# R7FA2A2AD register map
Vendor: Renesas Electronics Corporation; Series: RA2A2; File version: 1.20.02
CPU: CM23 r1p0, little endian, MPU, no FPU, VTOR, 2 interrupt priority bits, 32 interrupts
Registers are 8-bit, read-write, reset 0x0 unless marked. A register's access mark holds for its fields unless they carry their own. Offsets are from the block's base; [hi:lo] are bit positions; {n}, {i} and the like mark numbered series.

## AGTW0 — Low Power Asynchronous General Purpose Timer 0
Base 0x40084000
Same registers: AGTW1 0x40084100
0x00 AGT 32-bit reset 0xFFFFFFFF — AGT Counter Register
0x04 AGTCMA 32-bit reset 0xFFFFFFFF — AGT Compare Match A Register
0x08 AGTCMB 32-bit reset 0xFFFFFFFF — AGT Compare Match B Register
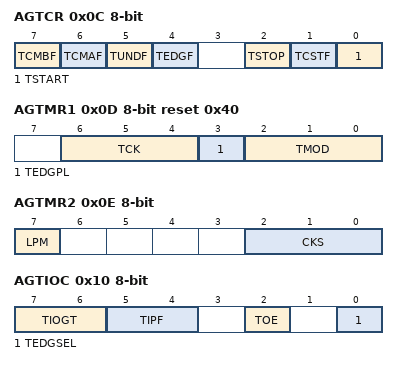
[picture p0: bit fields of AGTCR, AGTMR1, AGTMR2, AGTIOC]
0x0C AGTCR — AGT Control Register
  [7] TCMBF — Compare Match B Flag
    0=No match; 1=Match
  [6] TCMAF — Compare Match A Flag
    0=No match; 1=Match
  [5] TUNDF — Underflow Flag
    0=No underflow; 1=Underflow
  [4] TEDGF — Active Edge Judgment Flag
    0=No active edge received; 1=Active edge received
  [2] TSTOP wo — AGT Count Forced Stop
    0=Writing is invalid; 1=Count is forcibly stopped
  [1] TCSTF ro — AGT Count Status Flag
    0=Count stopped; 1=Count in progress
  [0] TSTART — AGT Count Start
    0=Count stops; 1=Count starts
0x0D AGTMR1 reset 0x40 — AGT Mode Register 1
  [6:4] TCK — Count Source
    0=PCLKB; 1=PCLKB/8; 3=PCLKB/2; 4=Divided clock AGTLCLK specified by CKS[2:0] bits in the AGTMR2 register; 5=Underflow event signal from AGTW0; 6=Divided clock AGTSCLK specified by CKS[2:0] bits in the AGTMR2 register; other=Others (Setting prohibited)
  [3] TEDGPL — Edge Polarity
    0=Single-edge; 1=Both-edge
  [2:0] TMOD — Operating Mode
    0=Timer mode; 1=Pulse output mode; 2=Event counter mode; 3=Pulse width measurement mode; 5=Pulse period measurement mode; other=Others (Setting prohibited)
0x0E AGTMR2 — AGT Mode Register 2
  [7] LPM — Low Power Mode
    0=Normal mode; 1=Low power mode
  [2:0] CKS — AGTLCLK or AGTSCLK Count Source Clock Frequency Division Ratio
    0=1/1; 1=1/2; 2=1/4; 3=1/8; 4=1/16; 5=1/32; 6=1/64; 7=1/128
0x0F AGTIOSEL — AGT Pin Select Register
  [4] TIES — AGTWIOn Pin Input Enable
    0=External event input is disabled during Software Standby mode; 1=External event input is enabled during Software Standby mode
0x10 AGTIOC — AGT I/O Control Register
  [7:6] TIOGT — Count Control
    0=Event is always counted; 1=Event is counted during polarity period specified for AGTWEEn pin; other=Others (Setting prohibited)
  [5:4] TIPF — Input Filter
    0=No filter; 1=Filter sampled at PCLKB; 2=Filter sampled at PCLKB/8; 3=Filter sampled at PCLKB/32
  [2] TOE — AGTWOn pin Output Enable
    0=AGTWOn pin output disabled; 1=AGTWOn pin output enabled
  [0] TEDGSEL — I/O Polarity Switch
0x11 AGTISR — AGT Event Pin Select Register
  [2] EEPS — AGTWEEn Polarity Selection
    0=An event is counted during the low-level period; 1=An event is counted during the high-level period
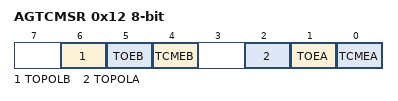
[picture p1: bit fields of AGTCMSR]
0x12 AGTCMSR — AGT Compare Match Function Select Register
  [6] TOPOLB — AGTWOBn Pin Polarity Select
    0=AGTWOBn pin output is started on low (normal output); 1=AGTWOBn pin output is started on high (inverted output)
  [5] TOEB — AGTWOBn Pin Output Enable
    0=AGTWOBn pin output disabled; 1=AGTWOBn pin output enabled
  [4] TCMEB — AGT Compare Match B Register Enable
    0=Compare match B register disabled; 1=Compare match B register enabled
  [2] TOPOLA — AGTWOAn Pin Polarity Select
    0=AGTWOAn pin output is started on low (normal output); 1=AGTWOAn pin output is started on high (inverted output)
  [1] TOEA — AGTWOAn Pin Output Enable
    0=AGTWOAn pin output disabled; 1=AGTWOAn pin output enabled
  [0] TCMEA — AGT Compare Match A Register Enable
    0=AGT Compare match A register disabled; 1=AGT Compare match A register enabled

## AGT0 — Low Power Asynchronous General Purpose Timer 0
Base 0x40084200
Same registers: AGT1 0x40084300, AGT2 0x40084400, AGT3 0x40084500, AGT4 0x40084600, AGT5 0x40084700, AGT6 0x40084800, AGT7 0x40084900
0x00 AGT 16-bit reset 0xFFFF — AGT Counter Register
0x02 AGTCMA 16-bit reset 0xFFFF — AGT Compare Match A Register
0x04 AGTCMB 16-bit reset 0xFFFF — AGT Compare Match B Register
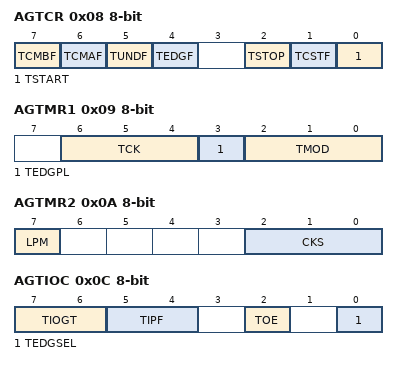
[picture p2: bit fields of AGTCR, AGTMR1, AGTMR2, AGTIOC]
0x08 AGTCR — AGT Control Register
  [7] TCMBF — Compare Match B Flag
    0=No match; 1=Match
  [6] TCMAF — Compare Match A Flag
    0=No match; 1=Match
  [5] TUNDF — Underflow Flag
    0=No underflow; 1=Underflow
  [4] TEDGF — Active Edge Judgment Flag
    0=No active edge received; 1=Active edge received
  [2] TSTOP wo — AGT Count Forced Stop
    0=Writing is invalid; 1=The count is forcibly stopped
  [1] TCSTF ro — AGT Count Status Flag
    0=Count stopped; 1=Count in progress
  [0] TSTART — AGT Count Start
    0=Count stops; 1=Count starts
0x09 AGTMR1 — AGT Mode Register 1
  [6:4] TCK — Count Source
    0=PCLKB; 1=PCLKB/8; 3=PCLKB/2; 4=Divided clock AGTLCLK specified by CKS[2:0] bits in the AGTMR2 register; 5=Underflow event signal from AGTx (x = 0, 2, 4, 6); 6=Divided clock AGTSCLK specified by CKS[2:0] bits in the AGTMR2 register; other=Others (Setting prohibited)
  [3] TEDGPL — Edge Polarity
    0=Single-edge; 1=Both-edge
  [2:0] TMOD — Operating Mode
    0=Timer mode; 1=Pulse output mode; 2=Event counter mode; 3=Pulse width measurement mode; 4=Pulse period measurement mode; other=Others (Setting prohibited)
0x0A AGTMR2 — AGT Mode Register 2
  [7] LPM — Low Power Mode
    0=Normal mode; 1=Low power mode
  [2:0] CKS — AGTLCLK or AGTSCLK Count Source Clock Frequency Division Ratio
    0=1/1; 1=1/2; 2=1/4; 3=1/8; 4=1/16; 5=1/32; 6=1/64; 7=1/128
0x0C AGTIOC — AGT I/O Control Register
  [7:6] TIOGT — Count Control
    0=Event is always counted; 1=Event is counted during polarity period specified for AGTEEn pin; other=Others (Setting prohibited)
  [5:4] TIPF — Input Filter
    0=No filter; 1=Filter sampled at PCLKB; 2=Filter sampled at PCLKB/8; 3=Filter sampled at PCLKB/32
  [2] TOE — AGTOn pin Output Enable
    0=AGTOn pin output disabled; 1=AGTOn pin output enabled
  [0] TEDGSEL — I/O Polarity Switch
0x0D AGTISR — AGT Event Pin Select Register
  [2] EEPS — AGTEEn Polarity Selection
    0=An event is counted during the low-level period; 1=An event is counted during the high-level period
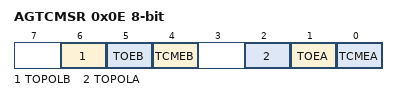
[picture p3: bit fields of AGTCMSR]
0x0E AGTCMSR — AGT Compare Match Function Select Register
  [6] TOPOLB — AGTOBn Pin Polarity Select
    0=AGTOBn pin output is started on low. i.e. normal output; 1=AGTOBn pin output is started on high. i.e. inverted output
  [5] TOEB — AGTOBn Pin Output Enable
    0=AGTOBn pin output disabled; 1=AGTOBn pin output enabled
  [4] TCMEB — AGT Compare Match B Register Enable
    0=Compare match B register disabled; 1=Compare match B register enabled
  [2] TOPOLA — AGTOAn Pin Polarity Select
    0=AGTOAn pin output is started on low. i.e. normal output; 1=AGTOAn pin output is started on high. i.e. inverted output
  [1] TOEA — AGTOAn Pin Output Enable
    0=AGTOAn pin output disabled; 1=AGTOAn pin output enabled
  [0] TCMEA — AGT Compare Match A Register Enable
    0=AGT Compare match A register disabled; 1=AGT Compare match A register enabled
0x0F AGTIOSEL — AGT Pin Select Register
  [4] TIES — AGTIOn Pin Input Enable
    0=External event input is disabled during Software Standby mode; 1=External event input is enabled during Software Standby mode

## MACL — 32-bit Multiply-Accumulator
Base 0x400A0000
{0x0+8i} MULB{i} (i=0..23) 32-bit — Multiplication Data Register Bn
{0xC0+8i} MULRL{i} (i=0..23) 32-bit — Multiplication Result Register {i}
{0xC4+8i} MULRH{i} (i=0..23) 32-bit (alternate view of MULRL{i}) — Multiplication Result Register {i}
0x180 MUL32U 32-bit — Multiplication Data Register A
0x184 MUL32S 32-bit (alternate view of MUL32U) — Multiplication Data Register A
0x188 MAC32U 32-bit (alternate view of MUL32U) — Multiplication Data Register A
0x18C MAC32S 32-bit (alternate view of MUL32U) — Multiplication Data Register A
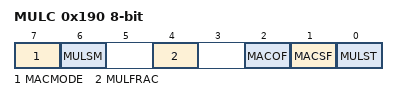
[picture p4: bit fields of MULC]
0x190 MULC — Multiplication Control Register
  [7] MACMODE — Operation Mode Selection
    0=Multiplication mode; 1=Multiply-accumulation mode
  [6] MULSM — Signedness Selection
    0=Unsigned; 1=Signed
  [4] MULFRAC — Fixed Point Mode Selection
    0=Disabled; 1=Enabled
  [2] MACOF ro — Multiply-accumulation Result (accumulation value) Overflow/Underflow Flag
    0=No overflow/underflow occurred; 1=Overflow/underflow occurred
  [1] MACSF ro — Multiply-accumulation Result (accumulation value) Sign Flag
    0=Positive accumulation value; 1=Negative accumulation value
  [0] MULST ro — Operation Processing Status Bit
    0=Completion of operation processing; 1=During operation processing
0x194 MULRCLR 32-bit — Multiplication Result Clear Register
